# irqctrlvec: IP-XACT component
VLNV spiritconsortium.org:Leon2RTL:irqctrlvec:1.2

## Bus interfaces (logical=physical port)
APBClk: slave spiritconsortium.org:busdef.clock:clock:1.0
  CLK=clk
APBReset: slave spiritconsortium.org:busdef.reset:reset:1.0
  RESETn=rst
ambaAPB: slave amba.com:AMBA2:APB:r2p0_4, memory map ambaAPB
  PSELx=psel, PENABLE=penable, PADDR=paddr, PWRITE=pwrite, PWDATA=pwdata, PRDATA=prdata, PCLK=clk, PRESETn=rst
MasterInt: master spiritconsortium.org:busdef.leon2:IntProc:v1.0
  IRL=irlout, IRQVEC=irlin, INTack=intack
SlaveInt: slave spiritconsortium.org:busdef.interrupt:interrupt:1.0
  IRQ=irq[14:0]

## Ports
in clk
in rst
in psel
in penable
in paddr[31:0]
in pwrite
in pwdata[31:0]
out prdata[31:0]
in irq[14:0]
in intack
in irlin[3:0]
out irlout[3:0]

## Address spaces and blocks
ambaAPB.defaultid4489939: base 0, range 64, width 32

## Registers
Registers are 32-bit, read-write, no defined reset value unless marked. A register's access mark holds for its fields unless they carry their own. Offsets are from the block's base; lines under a group give offsets from that group; [hi:lo] are bit positions; {n}, {i} and the like mark numbered series; 'fields as' and 'values as' point back to an identical list; <NAME> marks a mode.

## ambaAPB.defaultid4489939
Base 0x00000000
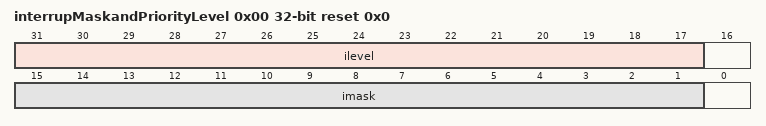
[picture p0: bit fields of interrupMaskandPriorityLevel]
0x00 interrupMaskandPriorityLevel reset 0x0 (reset mask 0xFFFE) — Interrupt Mask and Priority
  [31:17] ilevel — Indicates if an interrupt belongs to priority level 1 (bit=1) or 0 (bit=0)
  [15:1] imask — Indicates if an interrupt is masked (bit=0) or enabled (bit=1)
0x04 interruptPendingRegister — Indicates if an interrupt is pending
  [15:1] ipend — Indicates if an interrupt is pending (bit=1)
0x08 interruptForceRegister — Indicates if an interrupt is being forced
  [15:1] iforce — Indicates if an interrupt is being forced (bit=1)
0x0C interruptClearRegister — If written with a '1', will clear corresponding bit(s) in interrupt pending register. A read returns 0.
  [15:1] iforce
0x10 interruptReadClearPendingRegister

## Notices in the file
Copyright (c) 2006, 2008, 2009 The SPIRIT Consortium.
This work forms part of a deliverable of The SPIRIT Consortium.
Use of these materials are governed by the legal terms and conditions
outlined in the disclaimer available from www.spiritconsortium.org.
This source file is provided on an AS IS basis.  The SPIRIT
Consortium disclaims any warranty express or implied including
any warranty of merchantability and fitness for use for a
particular purpose.
The user of the source file shall indemnify and hold The SPIRIT
Consortium and its members harmless from any damages or liability.
